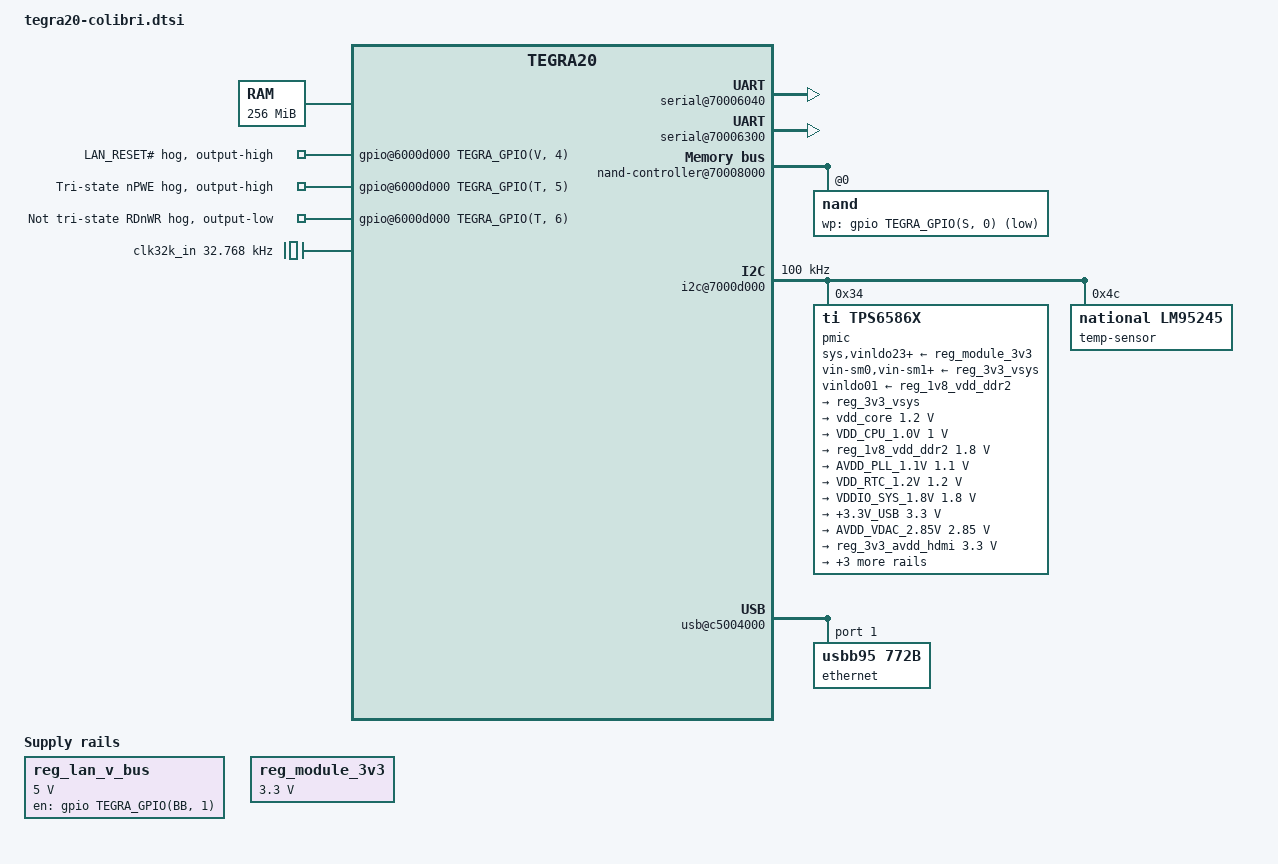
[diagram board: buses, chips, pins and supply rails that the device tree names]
#include "tegra20.dtsi"
/ {
	memory@0 {
		reg = <0x00000000 0x10000000>;
	};
	host1x@50000000 {
		hdmi@54280000 {
			nvidia,ddc-i2c-bus = <&hdmi_ddc>;
			nvidia,hpd-gpio =
				<&gpio TEGRA_GPIO(N, 7) GPIO_ACTIVE_HIGH>;
			pll-supply = <&reg_1v8_avdd_hdmi_pll>;
			vdd-supply = <&reg_3v3_avdd_hdmi>;
		};
	};
	gpio@6000d000 {
		lan-reset-n-hog {
			gpio-hog;
			gpios = <TEGRA_GPIO(V, 4) GPIO_ACTIVE_HIGH>;
			output-high;
			line-name = "LAN_RESET#";
		};
		npwe-hog {
			gpio-hog;
			gpios = <TEGRA_GPIO(T, 5) GPIO_ACTIVE_HIGH>;
			output-high;
			line-name = "Tri-state nPWE";
		};
		rdnwr-hog {
			gpio-hog;
			gpios = <TEGRA_GPIO(T, 6) GPIO_ACTIVE_HIGH>;
			output-low;
			line-name = "Not tri-state RDnWR";
		};
	};
	pinmux@70000014 {
		pinctrl-names = "default";
		pinctrl-0 = <&state_default>;
		state_default: pinmux {
			audio-refclk {
				nvidia,pins = "cdev1";
				nvidia,function = "plla_out";
				nvidia,pull = <TEGRA_PIN_PULL_NONE>;
				nvidia,tristate = <TEGRA_PIN_DISABLE>;
			};
			dap3 {
				nvidia,pins = "dap3";
				nvidia,function = "dap3";
				nvidia,pull = <TEGRA_PIN_PULL_NONE>;
				nvidia,tristate = <TEGRA_PIN_DISABLE>;
			};
			gpio-uac {
				nvidia,pins = "uac";
				nvidia,function = "rsvd2";
				nvidia,pull = <TEGRA_PIN_PULL_NONE>;
				nvidia,tristate = <TEGRA_PIN_DISABLE>;
			};
			gpio-pta {
				nvidia,pins = "pta";
				nvidia,function = "rsvd4";
				nvidia,pull = <TEGRA_PIN_PULL_NONE>;
				nvidia,tristate = <TEGRA_PIN_DISABLE>;
			};
			pmc {
				nvidia,pins = "pmc";
				nvidia,function = "pwr_on";
				nvidia,tristate = <TEGRA_PIN_DISABLE>;
			};
			gmi {
				nvidia,pins = "atc", "atd", "ate", "dap1",
					      "dap2", "dap4", "gmd", "gpu",
					      "irrx", "irtx", "spia", "spib",
					      "spic", "spid", "spie", "uca",
					      "ucb";
				nvidia,function = "gmi";
				nvidia,pull = <TEGRA_PIN_PULL_NONE>;
				nvidia,tristate = <TEGRA_PIN_ENABLE>;
			};
			gmi-gpio1 {
				nvidia,pins = "lpw0", "lsc1", "lsck", "lsda";
				nvidia,function = "hdmi";
				nvidia,tristate = <TEGRA_PIN_ENABLE>;
			};
			gmi-gpio2 {
				nvidia,pins = "lcsn", "ldc", "lm0", "lsdi";
				nvidia,function = "rsvd4";
				nvidia,tristate = <TEGRA_PIN_ENABLE>;
			};
			bl-on {
				nvidia,pins = "dta";
				nvidia,function = "rsvd1";
				nvidia,pull = <TEGRA_PIN_PULL_NONE>;
				nvidia,tristate = <TEGRA_PIN_ENABLE>;
			};
			sdc {
				nvidia,pins = "sdc";
				nvidia,function = "pwm";
				nvidia,tristate = <TEGRA_PIN_ENABLE>;
			};
			ddc {
				nvidia,pins = "ddc";
				nvidia,function = "i2c2";
				nvidia,pull = <TEGRA_PIN_PULL_UP>;
				nvidia,tristate = <TEGRA_PIN_ENABLE>;
			};
			ext-io {
				nvidia,pins = "dtf", "spdi";
				nvidia,function = "rsvd2";
				nvidia,pull = <TEGRA_PIN_PULL_NONE>;
				nvidia,tristate = <TEGRA_PIN_ENABLE>;
			};
			ulpi {
				nvidia,pins = "uaa", "uab", "uda";
				nvidia,function = "ulpi";
				nvidia,pull = <TEGRA_PIN_PULL_NONE>;
				nvidia,tristate = <TEGRA_PIN_DISABLE>;
			};
			ulpi-refclk {
				nvidia,pins = "cdev2";
				nvidia,function = "pllp_out4";
				nvidia,pull = <TEGRA_PIN_PULL_NONE>;
				nvidia,tristate = <TEGRA_PIN_DISABLE>;
			};
			hotplug-detect {
				nvidia,pins = "hdint";
				nvidia,function = "hdmi";
				nvidia,tristate = <TEGRA_PIN_ENABLE>;
			};
			i2c {
				nvidia,pins = "rm";
				nvidia,function = "i2c1";
				nvidia,pull = <TEGRA_PIN_PULL_NONE>;
				nvidia,tristate = <TEGRA_PIN_ENABLE>;
			};
			lm1 {
				nvidia,pins = "lm1";
				nvidia,function = "rsvd3";
				nvidia,tristate = <TEGRA_PIN_ENABLE>;
			};
			lcd {
				nvidia,pins = "ld0", "ld1", "ld2", "ld3",
					      "ld4", "ld5", "ld6", "ld7",
					      "ld8", "ld9", "ld10", "ld11",
					      "ld12", "ld13", "ld14", "ld15",
					      "ld16", "ld17", "lhs", "lsc0",
					      "lspi", "lvs";
				nvidia,function = "displaya";
				nvidia,tristate = <TEGRA_PIN_ENABLE>;
			};
			lcd-24 {
				nvidia,pins = "ldi", "lhp0", "lhp1", "lhp2",
					      "lpp", "lvp1";
				nvidia,function = "displaya";
				nvidia,tristate = <TEGRA_PIN_ENABLE>;
			};
			mmc {
				nvidia,pins = "atb", "gma";
				nvidia,function = "sdio4";
				nvidia,pull = <TEGRA_PIN_PULL_NONE>;
				nvidia,tristate = <TEGRA_PIN_ENABLE>;
			};
			mmccd {
				nvidia,pins = "gmb";
				nvidia,function = "gmi_int";
				nvidia,pull = <TEGRA_PIN_PULL_NONE>;
				nvidia,tristate = <TEGRA_PIN_ENABLE>;
			};
			mmc-8bit {
				nvidia,pins = "gme";
				nvidia,function = "sdio4";
				nvidia,pull = <TEGRA_PIN_PULL_NONE>;
				nvidia,tristate = <TEGRA_PIN_ENABLE>;
			};
			cif-mclk {
				nvidia,pins = "csus";
				nvidia,function = "vi_sensor_clk";
				nvidia,pull = <TEGRA_PIN_PULL_NONE>;
				nvidia,tristate = <TEGRA_PIN_ENABLE>;
			};
			cif {
				nvidia,pins = "dtb", "dtc", "dtd";
				nvidia,function = "vi";
				nvidia,pull = <TEGRA_PIN_PULL_NONE>;
				nvidia,tristate = <TEGRA_PIN_ENABLE>;
			};
			sdb_sdd {
				nvidia,pins = "sdb", "sdd";
				nvidia,function = "pwm";
				nvidia,tristate = <TEGRA_PIN_ENABLE>;
			};
			ssp {
				nvidia,pins = "slxa", "slxc", "slxd", "slxk";
				nvidia,function = "spi4";
				nvidia,pull = <TEGRA_PIN_PULL_NONE>;
				nvidia,tristate = <TEGRA_PIN_ENABLE>;
			};
			uart-a {
				nvidia,pins = "sdio1";
				nvidia,function = "uarta";
				nvidia,pull = <TEGRA_PIN_PULL_NONE>;
				nvidia,tristate = <TEGRA_PIN_ENABLE>;
			};
			uart-a-dsr {
				nvidia,pins = "lpw1";
				nvidia,function = "rsvd3";
				nvidia,tristate = <TEGRA_PIN_ENABLE>;
			};
			uart-a-dcd {
				nvidia,pins = "lpw2";
				nvidia,function = "hdmi";
				nvidia,tristate = <TEGRA_PIN_ENABLE>;
			};
			uart-b {
				nvidia,pins = "gmc";
				nvidia,function = "uartd";
				nvidia,pull = <TEGRA_PIN_PULL_NONE>;
				nvidia,tristate = <TEGRA_PIN_ENABLE>;
			};
			uart-c {
				nvidia,pins = "uad";
				nvidia,function = "irda";
				nvidia,pull = <TEGRA_PIN_PULL_NONE>;
				nvidia,tristate = <TEGRA_PIN_ENABLE>;
			};
			usb-cdet {
				nvidia,pins = "spdo";
				nvidia,function = "rsvd2";
				nvidia,pull = <TEGRA_PIN_PULL_NONE>;
				nvidia,tristate = <TEGRA_PIN_ENABLE>;
			};
			usbh-oc {
				nvidia,pins = "spih";
				nvidia,function = "spi2_alt";
				nvidia,pull = <TEGRA_PIN_PULL_NONE>;
				nvidia,tristate = <TEGRA_PIN_ENABLE>;
			};
			usbh-pen {
				nvidia,pins = "spig";
				nvidia,function = "spi2_alt";
				nvidia,pull = <TEGRA_PIN_PULL_NONE>;
				nvidia,tristate = <TEGRA_PIN_ENABLE>;
			};
			vga {
				nvidia,pins = "crtp";
				nvidia,function = "crt";
				nvidia,pull = <TEGRA_PIN_PULL_NONE>;
				nvidia,tristate = <TEGRA_PIN_ENABLE>;
			};
			i2c3 {
				nvidia,pins = "dtf";
				nvidia,function = "i2c3";
				nvidia,pull = <TEGRA_PIN_PULL_NONE>;
				nvidia,tristate = <TEGRA_PIN_ENABLE>;
			};
			jtag-rtck {
				nvidia,pins = "gpu7";
				nvidia,function = "rtck";
				nvidia,pull = <TEGRA_PIN_PULL_NONE>;
				nvidia,tristate = <TEGRA_PIN_ENABLE>;
			};
			gpio-gpv {
				nvidia,pins = "gpv";
				nvidia,function = "rsvd2";
				nvidia,pull = <TEGRA_PIN_PULL_NONE>;
				nvidia,tristate = <TEGRA_PIN_DISABLE>;
			};
			gpio-dte {
				nvidia,pins = "dte";
				nvidia,function = "rsvd1";
				nvidia,pull = <TEGRA_PIN_PULL_NONE>;
				nvidia,tristate = <TEGRA_PIN_DISABLE>;
			};
			nand {
				nvidia,pins = "kbca", "kbcb", "kbcc", "kbcd",
					      "kbce", "kbcf";
				nvidia,function = "nand";
				nvidia,pull = <TEGRA_PIN_PULL_NONE>;
				nvidia,tristate = <TEGRA_PIN_DISABLE>;
			};
			owr {
				nvidia,pins = "owc";
				nvidia,function = "owr";
				nvidia,pull = <TEGRA_PIN_PULL_NONE>;
				nvidia,tristate = <TEGRA_PIN_ENABLE>;
			};
			i2cp {
				nvidia,pins = "i2cp";
				nvidia,function = "i2cp";
				nvidia,pull = <TEGRA_PIN_PULL_NONE>;
				nvidia,tristate = <TEGRA_PIN_DISABLE>;
			};
			reset-out {
				nvidia,pins = "ata";
				nvidia,function = "gmi";
				nvidia,pull = <TEGRA_PIN_PULL_NONE>;
				nvidia,tristate = <TEGRA_PIN_DISABLE>;
			};
			spi1 {
				nvidia,pins = "spid", "spie", "spif";
				nvidia,function = "spi1";
				nvidia,pull = <TEGRA_PIN_PULL_NONE>;
				nvidia,tristate = <TEGRA_PIN_ENABLE>;
			};
			lvp0 {
				nvidia,pins = "lvp0";
				nvidia,function = "rsvd3";
				nvidia,tristate = <TEGRA_PIN_ENABLE>;
			};
		};
	};
	tegra_ac97: ac97@70002000 {
		status = "okay";
		nvidia,codec-reset-gpio =
			<&gpio TEGRA_GPIO(V, 0) GPIO_ACTIVE_HIGH>;
		nvidia,codec-sync-gpio =
			<&gpio TEGRA_GPIO(P, 0) GPIO_ACTIVE_HIGH>;
	};
	serial@70006040 {
		compatible = "nvidia,tegra20-hsuart";
		reset-names = "serial";
		/delete-property/ reg-shift;
	};
	serial@70006300 {
		compatible = "nvidia,tegra20-hsuart";
		reset-names = "serial";
		/delete-property/ reg-shift;
	};
	nand-controller@70008000 {
		status = "okay";
		nand@0 {
			reg = <0>;
			#address-cells = <1>;
			#size-cells = <1>;
			nand-bus-width = <8>;
			nand-on-flash-bbt;
			nand-ecc-algo = "bch";
			nand-is-boot-medium;
			nand-ecc-maximize;
			wp-gpios = <&gpio TEGRA_GPIO(S, 0) GPIO_ACTIVE_LOW>;
		};
	};
	i2c@7000c000 {
		clock-frequency = <400000>;
	};
	hdmi_ddc: i2c@7000c400 {
		clock-frequency = <10000>;
	};
	i2c@7000d000 {
		status = "okay";
		clock-frequency = <100000>;
		pmic@34 {
			compatible = "ti,tps6586x";
			reg = <0x34>;
			interrupts = <GIC_SPI 86 IRQ_TYPE_LEVEL_HIGH>;
			ti,system-power-controller;
			#gpio-cells = <2>;
			gpio-controller;
			sys-supply = <&reg_module_3v3>;
			vin-sm0-supply = <&reg_3v3_vsys>;
			vin-sm1-supply = <&reg_3v3_vsys>;
			vin-sm2-supply = <&reg_3v3_vsys>;
			vinldo01-supply = <&reg_1v8_vdd_ddr2>;
			vinldo23-supply = <&reg_module_3v3>;
			vinldo4-supply = <&reg_module_3v3>;
			vinldo678-supply = <&reg_module_3v3>;
			vinldo9-supply = <&reg_module_3v3>;
			regulators {
				reg_3v3_vsys: sys {
					regulator-name = "VSYS_3.3V";
					regulator-always-on;
				};
				vdd_core: sm0 {
					regulator-name = "VDD_CORE_1.2V";
					regulator-min-microvolt = <1200000>;
					regulator-max-microvolt = <1200000>;
					regulator-always-on;
				};
				sm1 {
					regulator-name = "VDD_CPU_1.0V";
					regulator-min-microvolt = <1000000>;
					regulator-max-microvolt = <1000000>;
					regulator-always-on;
				};
				reg_1v8_vdd_ddr2: sm2 {
					regulator-name = "VDD_DDR2_1.8V";
					regulator-min-microvolt = <1800000>;
					regulator-max-microvolt = <1800000>;
					regulator-always-on;
				};
				ldo1 {
					regulator-name = "AVDD_PLL_1.1V";
					regulator-min-microvolt = <1100000>;
					regulator-max-microvolt = <1100000>;
					regulator-always-on;
				};
				ldo2 {
					regulator-name = "VDD_RTC_1.2V";
					regulator-min-microvolt = <1200000>;
					regulator-max-microvolt = <1200000>;
				};
				ldo4 {
					regulator-name = "VDDIO_SYS_1.8V";
					regulator-min-microvolt = <1800000>;
					regulator-max-microvolt = <1800000>;
					regulator-always-on;
				};
				ldo5 {
					regulator-name = "+3.3V_USB";
					regulator-min-microvolt = <3300000>;
					regulator-max-microvolt = <3300000>;
					regulator-always-on;
				};
				ldo6 {
					regulator-name = "AVDD_VDAC_2.85V";
					regulator-min-microvolt = <2850000>;
					regulator-max-microvolt = <2850000>;
				};
				reg_3v3_avdd_hdmi: ldo7 {
					regulator-name = "AVDD_HDMI_3.3V";
					regulator-min-microvolt = <3300000>;
					regulator-max-microvolt = <3300000>;
				};
				reg_1v8_avdd_hdmi_pll: ldo8 {
					regulator-name = "AVDD_HDMI_PLL_1.8V";
					regulator-min-microvolt = <1800000>;
					regulator-max-microvolt = <1800000>;
				};
				ldo9 {
					regulator-name = "VDDIO_RX_DDR_2.85V";
					regulator-min-microvolt = <2850000>;
					regulator-max-microvolt = <2850000>;
					regulator-always-on;
				};
				ldo_rtc {
					regulator-name = "VCC_BATT";
					regulator-min-microvolt = <3300000>;
					regulator-max-microvolt = <3300000>;
					regulator-always-on;
				};
			};
		};
		temp-sensor@4c {
			compatible = "national,lm95245";
			reg = <0x4c>;
		};
	};
	pmc@7000e400 {
		nvidia,suspend-mode = <1>;
		nvidia,cpu-pwr-good-time = <5000>;
		nvidia,cpu-pwr-off-time = <5000>;
		nvidia,core-pwr-good-time = <3845 3845>;
		nvidia,core-pwr-off-time = <3875>;
		nvidia,sys-clock-req-active-high;
		core-supply = <&vdd_core>;
		i2c-thermtrip {
			nvidia,i2c-controller-id = <3>;
			nvidia,bus-addr = <0x34>;
			nvidia,reg-addr = <0x14>;
			nvidia,reg-data = <0x8>;
		};
	};
	memory-controller@7000f400 {
		emc-table@83250 {
			reg = <83250>;
			compatible = "nvidia,tegra20-emc-table";
			clock-frequency = <83250>;
			nvidia,emc-registers =   <0x00000005 0x00000011
				0x00000004 0x00000002 0x00000004 0x00000004
				0x00000001 0x0000000a 0x00000002 0x00000002
				0x00000001 0x00000001 0x00000003 0x00000004
				0x00000003 0x00000009 0x0000000c 0x0000025f
				0x00000000 0x00000003 0x00000003 0x00000002
				0x00000002 0x00000001 0x00000008 0x000000c8
				0x00000003 0x00000005 0x00000003 0x0000000c
				0x00000002 0x00000000 0x00000000 0x00000002
				0x00000000 0x00000000 0x00000083 0x00520006
				0x00000010 0x00000008 0x00000000 0x00000000
				0x00000000 0x00000000 0x00000000 0x00000000>;
		};
		emc-table@133200 {
			reg = <133200>;
			compatible = "nvidia,tegra20-emc-table";
			clock-frequency = <133200>;
			nvidia,emc-registers =   <0x00000008 0x00000019
				0x00000006 0x00000002 0x00000004 0x00000004
				0x00000001 0x0000000a 0x00000002 0x00000002
				0x00000002 0x00000001 0x00000003 0x00000004
				0x00000003 0x00000009 0x0000000c 0x0000039f
				0x00000000 0x00000003 0x00000003 0x00000002
				0x00000002 0x00000001 0x00000008 0x000000c8
				0x00000003 0x00000007 0x00000003 0x0000000c
				0x00000002 0x00000000 0x00000000 0x00000002
				0x00000000 0x00000000 0x00000083 0x00510006
				0x00000010 0x00000008 0x00000000 0x00000000
				0x00000000 0x00000000 0x00000000 0x00000000>;
		};
		emc-table@166500 {
			reg = <166500>;
			compatible = "nvidia,tegra20-emc-table";
			clock-frequency = <166500>;
			nvidia,emc-registers =   <0x0000000a 0x00000021
				0x00000008 0x00000003 0x00000004 0x00000004
				0x00000002 0x0000000a 0x00000003 0x00000003
				0x00000002 0x00000001 0x00000003 0x00000004
				0x00000003 0x00000009 0x0000000c 0x000004df
				0x00000000 0x00000003 0x00000003 0x00000003
				0x00000003 0x00000001 0x00000009 0x000000c8
				0x00000003 0x00000009 0x00000004 0x0000000c
				0x00000002 0x00000000 0x00000000 0x00000002
				0x00000000 0x00000000 0x00000083 0x004f0006
				0x00000010 0x00000008 0x00000000 0x00000000
				0x00000000 0x00000000 0x00000000 0x00000000>;
		};
		emc-table@333000 {
			reg = <333000>;
			compatible = "nvidia,tegra20-emc-table";
			clock-frequency = <333000>;
			nvidia,emc-registers =   <0x00000014 0x00000041
				0x0000000f 0x00000005 0x00000004 0x00000005
				0x00000003 0x0000000a 0x00000005 0x00000005
				0x00000004 0x00000001 0x00000003 0x00000004
				0x00000003 0x00000009 0x0000000c 0x000009ff
				0x00000000 0x00000003 0x00000003 0x00000005
				0x00000005 0x00000001 0x0000000e 0x000000c8
				0x00000003 0x00000011 0x00000006 0x0000000c
				0x00000002 0x00000000 0x00000000 0x00000002
				0x00000000 0x00000000 0x00000083 0x00380006
				0x00000010 0x00000008 0x00000000 0x00000000
				0x00000000 0x00000000 0x00000000 0x00000000>;
		};
	};
	usb@c5004000 {
		status = "okay";
		#address-cells = <1>;
		#size-cells = <0>;
		ethernet@1 {
			compatible = "usbb95,772b";
			reg = <1>;
			local-mac-address = [00 00 00 00 00 00];
		};
	};
	usb-phy@c5004000 {
		status = "okay";
		nvidia,phy-reset-gpio =
			<&gpio TEGRA_GPIO(V, 1) GPIO_ACTIVE_LOW>;
		vbus-supply = <&reg_lan_v_bus>;
	};
	clk32k_in: clock-xtal3 {
		compatible = "fixed-clock";
		#clock-cells = <0>;
		clock-frequency = <32768>;
	};
	opp-table-emc {
		/delete-node/ opp-760000000;
	};
	reg_lan_v_bus: regulator-lan-v-bus {
		compatible = "regulator-fixed";
		regulator-name = "LAN_V_BUS";
		regulator-min-microvolt = <5000000>;
		regulator-max-microvolt = <5000000>;
		enable-active-high;
		gpio = <&gpio TEGRA_GPIO(BB, 1) GPIO_ACTIVE_HIGH>;
	};
	reg_module_3v3: regulator-module-3v3 {
		compatible = "regulator-fixed";
		regulator-name = "+V3.3";
		regulator-min-microvolt = <3300000>;
		regulator-max-microvolt = <3300000>;
		regulator-always-on;
	};
	sound {
		compatible = "nvidia,tegra-audio-wm9712-colibri_t20",
			     "nvidia,tegra-audio-wm9712";
		nvidia,model = "Toradex Colibri T20";
		nvidia,audio-routing =
			"Headphone", "HPOUTL",
			"Headphone", "HPOUTR",
			"LineIn", "LINEINL",
			"LineIn", "LINEINR",
			"Mic", "MIC1";
		nvidia,ac97-controller = <&tegra_ac97>;
		clocks = <&tegra_car TEGRA20_CLK_PLL_A>,
			 <&tegra_car TEGRA20_CLK_PLL_A_OUT0>,
			 <&tegra_car TEGRA20_CLK_CDEV1>;
		clock-names = "pll_a", "pll_a_out0", "mclk";
	};
};
